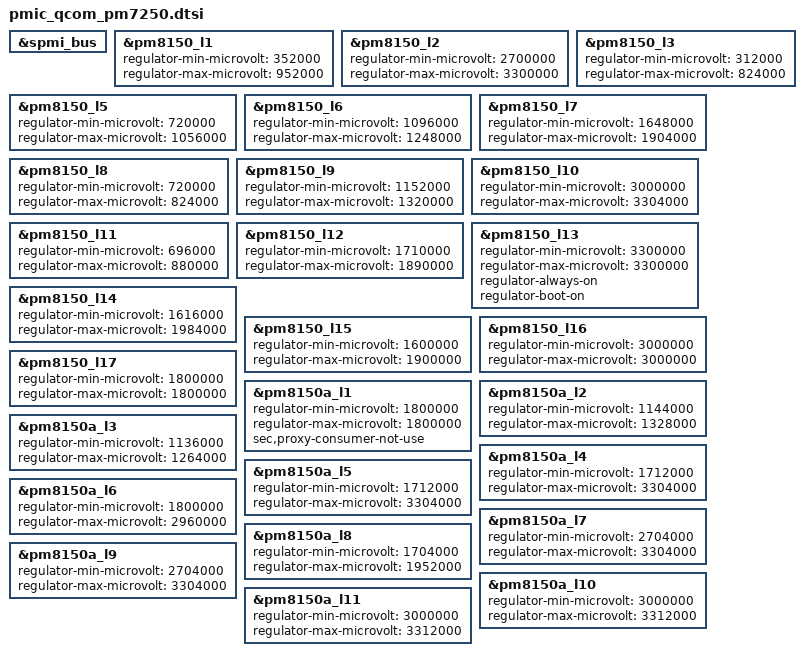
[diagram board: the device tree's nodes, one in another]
&spmi_bus {

};

&pm8150_l1 {
	regulator-min-microvolt = <352000>;
	regulator-max-microvolt = <952000>;
	 
	 
};
&pm8150_l2 {
	regulator-min-microvolt = <2700000>;
	regulator-max-microvolt = <3300000>;
	 
	 
};
&pm8150_l3 {
	regulator-min-microvolt = <312000>;
	regulator-max-microvolt = <824000>;
	 
	 
};
&pm8150_l5 {
	regulator-min-microvolt = <720000>;
	regulator-max-microvolt = <1056000>;
	 
	 
};
&pm8150_l6 {
	regulator-min-microvolt = <1096000>;
	regulator-max-microvolt = <1248000>;
	 
	 
};
&pm8150_l7 {
	regulator-min-microvolt = <1648000>;
	regulator-max-microvolt = <1904000>;
	 
	 
};
&pm8150_l8 {
	regulator-min-microvolt = <720000>;
	regulator-max-microvolt = <824000>;
	 
	 
};
&pm8150_l9 {
	regulator-min-microvolt = <1152000>;
	regulator-max-microvolt = <1320000>;
	 
	 
};
&pm8150_l10 {
	regulator-min-microvolt = <3000000>;
	regulator-max-microvolt = <3304000>;
	 
	 
};
&pm8150_l11 {
	regulator-min-microvolt = <696000>;
	regulator-max-microvolt = <880000>;
	 
	 
};
&pm8150_l12 {
	regulator-min-microvolt = <1710000>;
	regulator-max-microvolt = <1890000>;
	 
	 
};
&pm8150_l13 {
	regulator-min-microvolt = <3300000>;
	regulator-max-microvolt = <3300000>;
	 regulator-always-on;regulator-boot-on;
	 
};
&pm8150_l14 {
	regulator-min-microvolt = <1616000>;
	regulator-max-microvolt = <1984000>;
	 
	 
};
&pm8150_l15 {
	regulator-min-microvolt = <1600000>;
	regulator-max-microvolt = <1900000>;
	 
	 
};
&pm8150_l16 {
	regulator-min-microvolt = <3000000>;
	regulator-max-microvolt = <3000000>;
	 
	 
};
&pm8150_l17 {
	regulator-min-microvolt = <1800000>;
	regulator-max-microvolt = <1800000>;
	 
	 
};
&pm8150a_l1 {
	regulator-min-microvolt = <1800000>;
	regulator-max-microvolt = <1800000>;
	 
	sec,proxy-consumer-not-use;
};
&pm8150a_l2 {
	regulator-min-microvolt = <1144000>;
	regulator-max-microvolt = <1328000>;
	 
	 
};
&pm8150a_l3 {
	regulator-min-microvolt = <1136000>;
	regulator-max-microvolt = <1264000>;
	 
	 
};
&pm8150a_l4 {
	regulator-min-microvolt = <1712000>;
	regulator-max-microvolt = <3304000>;
	 
	 
};
&pm8150a_l5 {
	regulator-min-microvolt = <1712000>;
	regulator-max-microvolt = <3304000>;
	 
	 
};
&pm8150a_l6 {
	regulator-min-microvolt = <1800000>;
	regulator-max-microvolt = <2960000>;
	 
	 
};
&pm8150a_l7 {
	regulator-min-microvolt = <2704000>;
	regulator-max-microvolt = <3304000>;
	 
	 
};
&pm8150a_l8 {
	regulator-min-microvolt = <1704000>;
	regulator-max-microvolt = <1952000>;
	 
	 
};
&pm8150a_l9 {
	regulator-min-microvolt = <2704000>;
	regulator-max-microvolt = <3304000>;
	 
	 
};
&pm8150a_l10 {
	regulator-min-microvolt = <3000000>;
	regulator-max-microvolt = <3312000>;
	 
	 
};
&pm8150a_l11 {
	regulator-min-microvolt = <3000000>;
	regulator-max-microvolt = <3312000>;
	 
	 
};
